VERSION ""

NS_ :

BS_:

BU_: FrontNode RearNode

BO_ 512 Front_FastSensors: 18 FrontNode
 SG_ SteeringAngle_rawAngle : 0|16@1+ (1,0) [0|4095] "" Vector__XXX
 SG_ SteeringAngle_angleCentiDegrees : 16|16@1+ (1,0) [0|35999] "cdeg" Vector__XXX
 SG_ SteeringAngle_magnitude : 32|16@1+ (1,0) [0|65535] "" Vector__XXX
 SG_ SteeringAngle_agc : 48|8@1+ (1,0) [0|255] "" Vector__XXX
 SG_ SteeringAngle_status : 56|8@1+ (1,0) [0|255] "" Vector__XXX
 SG_ SteeringAngle_error : 64|16@1- (1,0) [-32768|32767] "" Vector__XXX
 SG_ FrontBrakePressure_raw : 87|16@0+ (1,0) [0|4095] "" Vector__XXX
 SG_ RearBrakePressure_raw : 103|16@0+ (1,0) [0|4095] "" Vector__XXX
 SG_ FLSuspension_raw : 119|16@0+ (1,0) [0|4095] "" Vector__XXX
 SG_ FRSuspension_raw : 135|16@0+ (1,0) [0|4095] "" Vector__XXX

BO_ 513 Front_IMU_Data: 54 FrontNode
 SG_ IMU_Data_version : 0|8@1+ (1,0) [0|255] "" Vector__XXX
 SG_ IMU_Data_validMask : 8|8@1+ (1,0) [0|255] "" Vector__XXX
 SG_ IMU_Data_accel_x : 16|32@1- (1,0) [0|0] "m/s^2" Vector__XXX
 SG_ IMU_Data_accel_y : 48|32@1- (1,0) [0|0] "m/s^2" Vector__XXX
 SG_ IMU_Data_accel_z : 80|32@1- (1,0) [0|0] "m/s^2" Vector__XXX
 SG_ IMU_Data_angular_vel_x : 112|32@1- (1,0) [0|0] "rad/s" Vector__XXX
 SG_ IMU_Data_angular_vel_y : 144|32@1- (1,0) [0|0] "rad/s" Vector__XXX
 SG_ IMU_Data_angular_vel_z : 176|32@1- (1,0) [0|0] "rad/s" Vector__XXX
 SG_ IMU_Data_linear_accel_x : 208|32@1- (1,0) [0|0] "m/s^2" Vector__XXX
 SG_ IMU_Data_linear_accel_y : 240|32@1- (1,0) [0|0] "m/s^2" Vector__XXX
 SG_ IMU_Data_linear_accel_z : 272|32@1- (1,0) [0|0] "m/s^2" Vector__XXX
 SG_ IMU_Data_rotation_i : 304|32@1- (1,0) [0|0] "" Vector__XXX
 SG_ IMU_Data_rotation_j : 336|32@1- (1,0) [0|0] "" Vector__XXX
 SG_ IMU_Data_rotation_k : 368|32@1- (1,0) [0|0] "" Vector__XXX
 SG_ IMU_Data_rotation_real : 400|32@1- (1,0) [0|0] "" Vector__XXX

BO_ 514 Front_IMU_Stats: 12 FrontNode
 SG_ IMU_Stats_version : 0|8@1+ (1,0) [0|255] "" Vector__XXX
 SG_ IMU_Stats_validMask : 8|8@1+ (1,0) [0|255] "" Vector__XXX
 SG_ IMU_Stats_error : 16|16@1- (1,0) [-32768|32767] "" Vector__XXX
 SG_ IMU_Stats_accelAccuracy : 32|8@1+ (1,0) [0|255] "" Vector__XXX
 SG_ IMU_Stats_gyroAccuracy : 40|8@1+ (1,0) [0|255] "" Vector__XXX
 SG_ IMU_Stats_linearAccelAccuracy : 48|8@1+ (1,0) [0|255] "" Vector__XXX
 SG_ IMU_Stats_rotationAccuracy : 56|8@1+ (1,0) [0|255] "" Vector__XXX
 SG_ IMU_Stats_rotation_acc_rad : 64|32@1- (1,0) [0|0] "rad" Vector__XXX

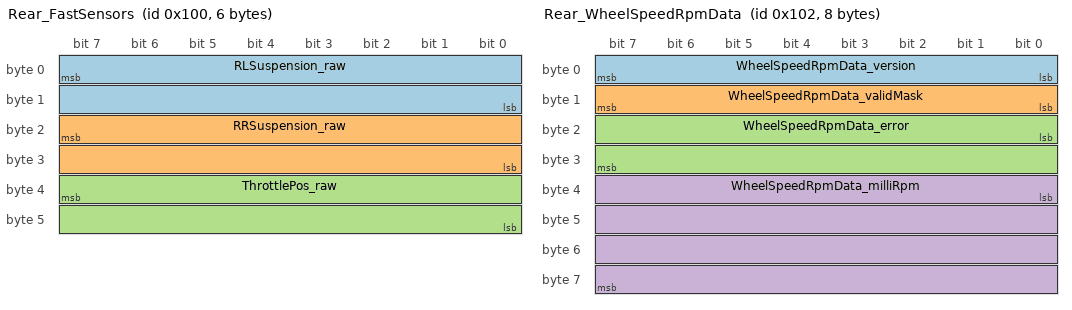
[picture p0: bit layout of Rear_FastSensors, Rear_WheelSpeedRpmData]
BO_ 256 Rear_FastSensors: 6 RearNode
 SG_ RLSuspension_raw : 7|16@0+ (1,0) [0|4095] "" Vector__XXX
 SG_ RRSuspension_raw : 23|16@0+ (1,0) [0|4095] "" Vector__XXX
 SG_ ThrottlePos_raw : 39|16@0+ (1,0) [0|4095] "" Vector__XXX

BO_ 257 Rear_IRCVTTemp: 14 RearNode
 SG_ IRCVTTemp_version : 0|8@1+ (1,0) [0|255] "" Vector__XXX
 SG_ IRCVTTemp_validMask : 8|8@1+ (1,0) [0|255] "" Vector__XXX
 SG_ IRCVTTemp_ambientCentiDegrees : 16|32@1- (1,0) [-2147483648|2147483647] "cdeg" Vector__XXX
 SG_ IRCVTTemp_objectCentiDegrees : 48|32@1- (1,0) [-2147483648|2147483647] "cdeg" Vector__XXX
 SG_ IRCVTTemp_emissivityTenThousandths : 80|16@1+ (1,0) [0|10000] "" Vector__XXX
 SG_ IRCVTTemp_error : 96|16@1- (1,0) [-32768|32767] "" Vector__XXX

BO_ 258 Rear_WheelSpeedRpmData: 8 RearNode
 SG_ WheelSpeedRpmData_version : 0|8@1+ (1,0) [0|255] "" Vector__XXX
 SG_ WheelSpeedRpmData_validMask : 8|8@1+ (1,0) [0|255] "" Vector__XXX
 SG_ WheelSpeedRpmData_error : 16|16@1- (1,0) [-32768|32767] "" Vector__XXX
 SG_ WheelSpeedRpmData_milliRpm : 32|32@1- (1,0) [-2147483648|2147483647] "milli_rpm" Vector__XXX

BO_ 259 Rear_WheelSpeedRpmStats: 22 RearNode
 SG_ WheelSpeedRpmStats_version : 0|8@1+ (1,0) [0|255] "" Vector__XXX
 SG_ WheelSpeedRpmStats_validMask : 8|8@1+ (1,0) [0|255] "" Vector__XXX
 SG_ WheelSpeedRpmStats_rawAdc : 16|16@1+ (1,0) [0|4095] "" Vector__XXX
 SG_ WheelSpeedRpmStats_rawAngle : 32|16@1+ (1,0) [0|4095] "" Vector__XXX
 SG_ WheelSpeedRpmStats_angleCentiDegrees : 48|16@1+ (1,0) [0|35999] "cdeg" Vector__XXX
 SG_ WheelSpeedRpmStats_sampleIntervalMicros : 64|32@1+ (1,0) [0|4294967295] "us" Vector__XXX
 SG_ WheelSpeedRpmStats_rawMilliRpm : 96|32@1- (1,0) [-2147483648|2147483647] "milli_rpm" Vector__XXX
 SG_ WheelSpeedRpmStats_filteredMilliRpm : 128|32@1- (1,0) [-2147483648|2147483647] "milli_rpm" Vector__XXX
 SG_ WheelSpeedRpmStats_error : 160|16@1- (1,0) [-32768|32767] "" Vector__XXX

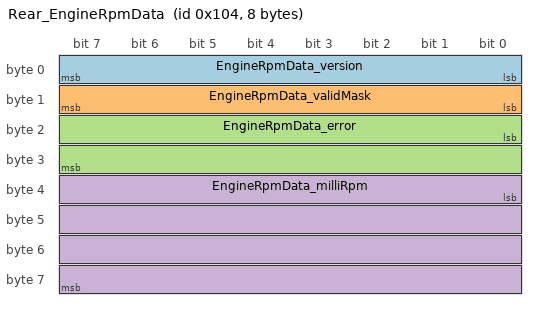
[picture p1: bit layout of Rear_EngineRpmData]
BO_ 260 Rear_EngineRpmData: 8 RearNode
 SG_ EngineRpmData_version : 0|8@1+ (1,0) [0|255] "" Vector__XXX
 SG_ EngineRpmData_validMask : 8|8@1+ (1,0) [0|255] "" Vector__XXX
 SG_ EngineRpmData_error : 16|16@1- (1,0) [-32768|32767] "" Vector__XXX
 SG_ EngineRpmData_milliRpm : 32|32@1- (1,0) [-2147483648|2147483647] "milli_rpm" Vector__XXX

BO_ 261 Rear_EngineRpmStats: 32 RearNode
 SG_ EngineRpmStats_version : 0|8@1+ (1,0) [0|255] "" Vector__XXX
 SG_ EngineRpmStats_validMask : 8|8@1+ (1,0) [0|255] "" Vector__XXX
 SG_ EngineRpmStats_pulseIntervalMicros : 16|32@1+ (1,0) [0|4294967295] "us" Vector__XXX
 SG_ EngineRpmStats_averagedPulseIntervalMicros : 48|32@1+ (1,0) [0|4294967295] "us" Vector__XXX
 SG_ EngineRpmStats_pendingOutlierIntervalMicros : 80|32@1+ (1,0) [0|4294967295] "us" Vector__XXX
 SG_ EngineRpmStats_sampleAgeMicros : 112|32@1+ (1,0) [0|4294967295] "us" Vector__XXX
 SG_ EngineRpmStats_acceptedPulseCount : 144|32@1+ (1,0) [0|4294967295] "" Vector__XXX
 SG_ EngineRpmStats_rejectedPulseCount : 176|32@1+ (1,0) [0|4294967295] "" Vector__XXX
 SG_ EngineRpmStats_milliRpm : 208|32@1- (1,0) [-2147483648|2147483647] "milli_rpm" Vector__XXX
 SG_ EngineRpmStats_error : 240|16@1- (1,0) [-32768|32767] "" Vector__XXX

SIG_VALTYPE_ 513 IMU_Data_accel_x : 1;
SIG_VALTYPE_ 513 IMU_Data_accel_y : 1;
SIG_VALTYPE_ 513 IMU_Data_accel_z : 1;
SIG_VALTYPE_ 513 IMU_Data_angular_vel_x : 1;
SIG_VALTYPE_ 513 IMU_Data_angular_vel_y : 1;
SIG_VALTYPE_ 513 IMU_Data_angular_vel_z : 1;
SIG_VALTYPE_ 513 IMU_Data_linear_accel_x : 1;
SIG_VALTYPE_ 513 IMU_Data_linear_accel_y : 1;
SIG_VALTYPE_ 513 IMU_Data_linear_accel_z : 1;
SIG_VALTYPE_ 513 IMU_Data_rotation_i : 1;
SIG_VALTYPE_ 513 IMU_Data_rotation_j : 1;
SIG_VALTYPE_ 513 IMU_Data_rotation_k : 1;
SIG_VALTYPE_ 513 IMU_Data_rotation_real : 1;
SIG_VALTYPE_ 514 IMU_Stats_rotation_acc_rad : 1;
